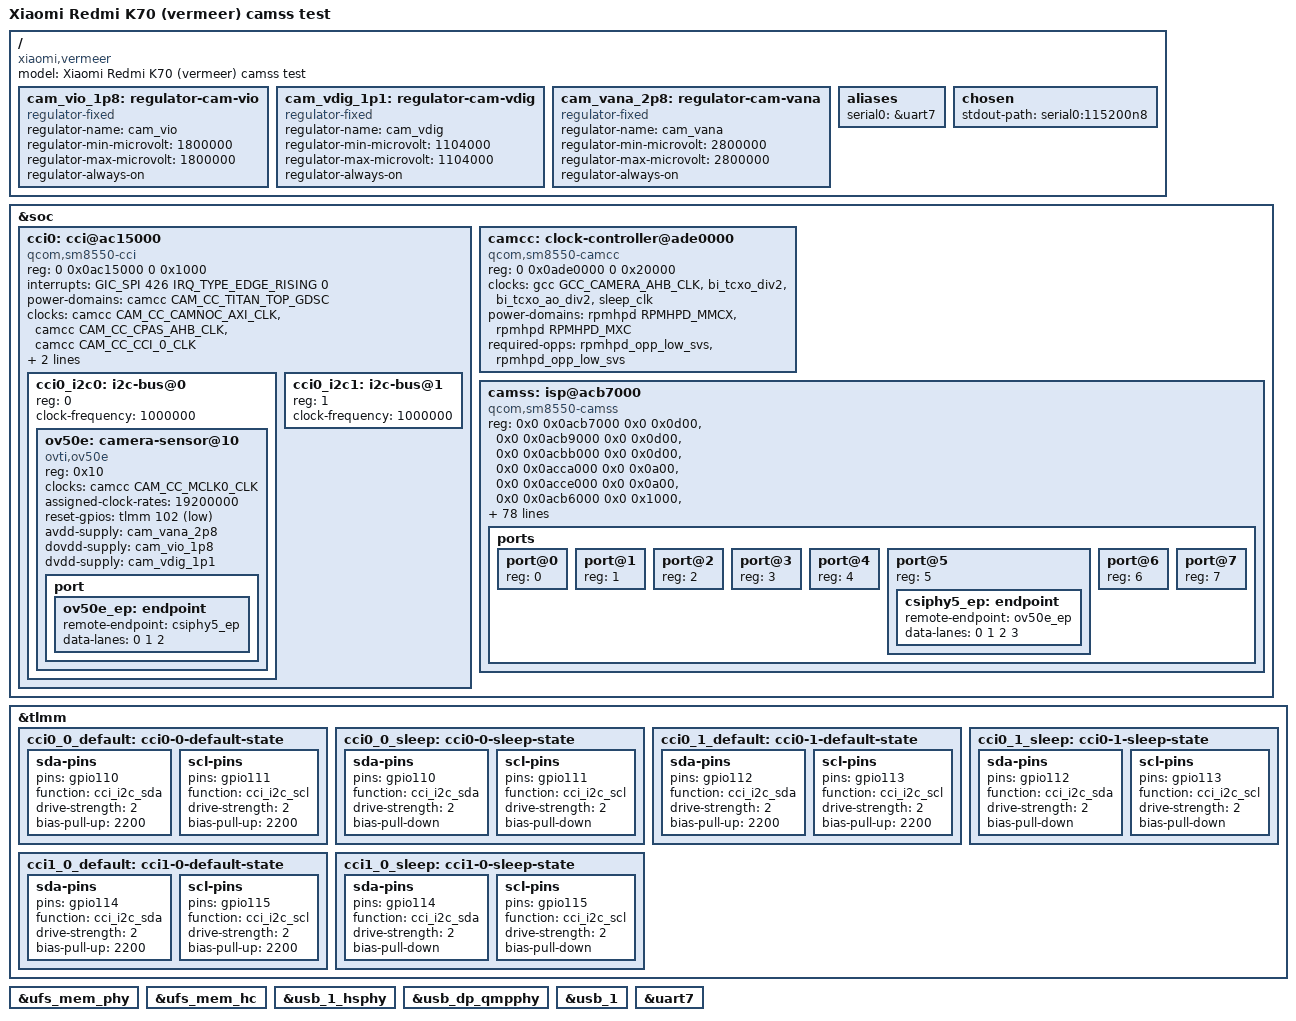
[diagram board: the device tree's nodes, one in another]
// SPDX-License-Identifier: BSD-3-Clause
/*
 * vermeer (Redmi K70, SM8550/kalama) camera bring-up test DT.
 * Xiaomi stripped all camera nodes from the stock DTBs (verified across
 * vendor_boot 8-FDT blob, dtbo.img 32 entries, boot.img) so this file
 * re-creates them from upstream sm8550.dtsi (camss/cci/camcc blocks are
 * platform constants) plus the vermeer sensor facts extracted from the
 * stock super.img odm partition:
 *   main: OV50E (OVX8000) @ CCI0/I2C0, 7-bit 0x10, chip id 0x5045
 *   rails: cam_vio=1.8V cam_vdig=1.1V cam_vana=2.8V (fixed placeholders
 *          until the real PM8550 LDO mapping is confirmed on-device)
 */
/dts-v1/;

#include "sm8550.dtsi"
#include <dt-bindings/clock/qcom,sm8550-camcc.h>
/* interconnect ids + tags (dtsi pulls sm8550-rpmh.h but not qcom,icc.h;
   be explicit so the camss interconnects below always resolve) */
#include <dt-bindings/interconnect/qcom,sm8550-rpmh.h>
#include <dt-bindings/interconnect/qcom,icc.h>

/ {
	model = "Xiaomi Redmi K70 (vermeer) camss test";
	compatible = "xiaomi,vermeer", "qcom,sm8550";

	cam_vio_1p8: regulator-cam-vio {
		compatible = "regulator-fixed";
		regulator-name = "cam_vio";
		regulator-min-microvolt = <1800000>;
		regulator-max-microvolt = <1800000>;
		regulator-always-on;
	};

	cam_vdig_1p1: regulator-cam-vdig {
		compatible = "regulator-fixed";
		regulator-name = "cam_vdig";
		regulator-min-microvolt = <1104000>;
		regulator-max-microvolt = <1104000>;
		regulator-always-on;
	};

	cam_vana_2p8: regulator-cam-vana {
		compatible = "regulator-fixed";
		regulator-name = "cam_vana";
		regulator-min-microvolt = <2800000>;
		regulator-max-microvolt = <2800000>;
		regulator-always-on;
	};
};

&soc {
		cci0: cci@ac15000 {
			compatible = "qcom,sm8550-cci", "qcom,msm8996-cci";
			reg = <0 0x0ac15000 0 0x1000>;
			interrupts = <GIC_SPI 426 IRQ_TYPE_EDGE_RISING 0>;
			power-domains = <&camcc CAM_CC_TITAN_TOP_GDSC>;
			clocks = <&camcc CAM_CC_CAMNOC_AXI_CLK>,
				 <&camcc CAM_CC_CPAS_AHB_CLK>,
				 <&camcc CAM_CC_CCI_0_CLK>;
			clock-names = "camnoc_axi",
				      "cpas_ahb",
				      "cci";
			pinctrl-0 = <&cci0_0_default &cci0_1_default>;
			pinctrl-1 = <&cci0_0_sleep &cci0_1_sleep>;
			pinctrl-names = "default", "sleep";
			status = "okay";
			#address-cells = <1>;
			#size-cells = <0>;

			cci0_i2c0: i2c-bus@0 {
				reg = <0>;
				clock-frequency = <1000000>;
				#address-cells = <1>;
				#size-cells = <0>;
			
		ov50e: camera-sensor@10 {
			compatible = "ovti,ov50e";
			reg = <0x10>;

			clocks = <&camcc CAM_CC_MCLK0_CLK>;
			clock-names = "xclk";
			/* vermeer dtbo: clock-rates = <19200000>; reset via gpio102,
			   gpio118 = custom (lens/ois power) - see overlay gpios tbl */
			assigned-clock-rates = <19200000>;
			reset-gpios = <&tlmm 102 GPIO_ACTIVE_LOW>;

			avdd-supply = <&cam_vana_2p8>;
			dovdd-supply = <&cam_vio_1p8>;
			dvdd-supply = <&cam_vdig_1p1>;

			status = "okay";

			port {
				ov50e_ep: endpoint {
					remote-endpoint = <&csiphy5_ep>;
					data-lanes = <0 1 2>;
				};
			};
		};
			};

			cci0_i2c1: i2c-bus@1 {
				reg = <1>;
				clock-frequency = <1000000>;
				#address-cells = <1>;
				#size-cells = <0>;
			};
		};

		camcc: clock-controller@ade0000 {
			compatible = "qcom,sm8550-camcc";
			reg = <0 0x0ade0000 0 0x20000>;
			clocks = <&gcc GCC_CAMERA_AHB_CLK>,
				 <&bi_tcxo_div2>,
				 <&bi_tcxo_ao_div2>,
				 <&sleep_clk>;
			power-domains = <&rpmhpd RPMHPD_MMCX>,
					<&rpmhpd RPMHPD_MXC>;
			required-opps = <&rpmhpd_opp_low_svs>,
					<&rpmhpd_opp_low_svs>;
			#clock-cells = <1>;
			#reset-cells = <1>;
			#power-domain-cells = <1>;
		};

		camss: isp@acb7000 {
			compatible = "qcom,sm8550-camss";

			reg = <0x0 0x0acb7000 0x0 0x0d00>,
			      <0x0 0x0acb9000 0x0 0x0d00>,
			      <0x0 0x0acbb000 0x0 0x0d00>,
			      <0x0 0x0acca000 0x0 0x0a00>,
			      <0x0 0x0acce000 0x0 0x0a00>,
			      <0x0 0x0acb6000 0x0 0x1000>,
			      <0x0 0x0ace4000 0x0 0x2000>,
			      <0x0 0x0ace6000 0x0 0x2000>,
			      <0x0 0x0ace8000 0x0 0x2000>,
			      <0x0 0x0acea000 0x0 0x2000>,
			      <0x0 0x0acec000 0x0 0x2000>,
			      <0x0 0x0acee000 0x0 0x2000>,
			      <0x0 0x0acf0000 0x0 0x2000>,
			      <0x0 0x0acf2000 0x0 0x2000>,
			      <0x0 0x0ac62000 0x0 0xf000>,
			      <0x0 0x0ac71000 0x0 0xf000>,
			      <0x0 0x0ac80000 0x0 0xf000>,
			      <0x0 0x0accb000 0x0 0x1800>,
			      <0x0 0x0accf000 0x0 0x1800>;
			reg-names = "csid0",
				    "csid1",
				    "csid2",
				    "csid_lite0",
				    "csid_lite1",
				    "csid_wrapper",
				    "csiphy0",
				    "csiphy1",
				    "csiphy2",
				    "csiphy3",
				    "csiphy4",
				    "csiphy5",
				    "csiphy6",
				    "csiphy7",
				    "vfe0",
				    "vfe1",
				    "vfe2",
				    "vfe_lite0",
				    "vfe_lite1";

			clocks = <&camcc CAM_CC_CAMNOC_AXI_CLK>,
				 <&camcc CAM_CC_CPAS_AHB_CLK>,
				 <&camcc CAM_CC_CPAS_FAST_AHB_CLK>,
				 <&camcc CAM_CC_CPAS_IFE_LITE_CLK>,
				 <&camcc CAM_CC_CPAS_IFE_0_CLK>,
				 <&camcc CAM_CC_CPAS_IFE_1_CLK>,
				 <&camcc CAM_CC_CPAS_IFE_2_CLK>,
				 <&camcc CAM_CC_CSID_CLK>,
				 <&camcc CAM_CC_CSIPHY0_CLK>,
				 <&camcc CAM_CC_CSI0PHYTIMER_CLK>,
				 <&camcc CAM_CC_CSIPHY1_CLK>,
				 <&camcc CAM_CC_CSI1PHYTIMER_CLK>,
				 <&camcc CAM_CC_CSIPHY2_CLK>,
				 <&camcc CAM_CC_CSI2PHYTIMER_CLK>,
				 <&camcc CAM_CC_CSIPHY3_CLK>,
				 <&camcc CAM_CC_CSI3PHYTIMER_CLK>,
				 <&camcc CAM_CC_CSIPHY4_CLK>,
				 <&camcc CAM_CC_CSI4PHYTIMER_CLK>,
				 <&camcc CAM_CC_CSIPHY5_CLK>,
				 <&camcc CAM_CC_CSI5PHYTIMER_CLK>,
				 <&camcc CAM_CC_CSIPHY6_CLK>,
				 <&camcc CAM_CC_CSI6PHYTIMER_CLK>,
				 <&camcc CAM_CC_CSIPHY7_CLK>,
				 <&camcc CAM_CC_CSI7PHYTIMER_CLK>,
				 <&camcc CAM_CC_CSID_CSIPHY_RX_CLK>,
				 <&gcc GCC_CAMERA_HF_AXI_CLK>,
				 <&camcc CAM_CC_IFE_0_CLK>,
				 <&camcc CAM_CC_IFE_0_FAST_AHB_CLK>,
				 <&camcc CAM_CC_IFE_1_CLK>,
				 <&camcc CAM_CC_IFE_1_FAST_AHB_CLK>,
				 <&camcc CAM_CC_IFE_2_CLK>,
				 <&camcc CAM_CC_IFE_2_FAST_AHB_CLK>,
				 <&camcc CAM_CC_IFE_LITE_CLK>,
				 <&camcc CAM_CC_IFE_LITE_AHB_CLK>,
				 <&camcc CAM_CC_IFE_LITE_CPHY_RX_CLK>,
				 <&camcc CAM_CC_IFE_LITE_CSID_CLK>;
			clock-names = "camnoc_axi",
				      "cpas_ahb",
				      "cpas_fast_ahb_clk",
				      "cpas_ife_lite",
				      "cpas_vfe0",
				      "cpas_vfe1",
				      "cpas_vfe2",
				      "csid",
				      "csiphy0",
				      "csiphy0_timer",
				      "csiphy1",
				      "csiphy1_timer",
				      "csiphy2",
				      "csiphy2_timer",
				      "csiphy3",
				      "csiphy3_timer",
				      "csiphy4",
				      "csiphy4_timer",
				      "csiphy5",
				      "csiphy5_timer",
				      "csiphy6",
				      "csiphy6_timer",
				      "csiphy7",
				      "csiphy7_timer",
				      "csiphy_rx",
				      "gcc_axi_hf",
				      "vfe0",
				      "vfe0_fast_ahb",
				      "vfe1",
				      "vfe1_fast_ahb",
				      "vfe2",
				      "vfe2_fast_ahb",
				      "vfe_lite",
				      "vfe_lite_ahb",
				      "vfe_lite_cphy_rx",
				      "vfe_lite_csid";

			interrupts = <GIC_SPI 601 IRQ_TYPE_EDGE_RISING 0>,
				     <GIC_SPI 603 IRQ_TYPE_EDGE_RISING 0>,
				     <GIC_SPI 431 IRQ_TYPE_EDGE_RISING 0>,
				     <GIC_SPI 605 IRQ_TYPE_EDGE_RISING 0>,
				     <GIC_SPI 376 IRQ_TYPE_EDGE_RISING 0>,
				     <GIC_SPI 477 IRQ_TYPE_EDGE_RISING 0>,
				     <GIC_SPI 478 IRQ_TYPE_EDGE_RISING 0>,
				     <GIC_SPI 479 IRQ_TYPE_EDGE_RISING 0>,
				     <GIC_SPI 448 IRQ_TYPE_EDGE_RISING 0>,
				     <GIC_SPI 122 IRQ_TYPE_EDGE_RISING 0>,
				     <GIC_SPI 89 IRQ_TYPE_EDGE_RISING 0>,
				     <GIC_SPI 278 IRQ_TYPE_EDGE_RISING 0>,
				     <GIC_SPI 277 IRQ_TYPE_EDGE_RISING 0>,
				     <GIC_SPI 602 IRQ_TYPE_EDGE_RISING 0>,
				     <GIC_SPI 604 IRQ_TYPE_EDGE_RISING 0>,
				     <GIC_SPI 688 IRQ_TYPE_EDGE_RISING 0>,
				     <GIC_SPI 606 IRQ_TYPE_EDGE_RISING 0>,
				     <GIC_SPI 377 IRQ_TYPE_EDGE_RISING 0>;
			interrupt-names = "csid0",
					  "csid1",
					  "csid2",
					  "csid_lite0",
					  "csid_lite1",
					  "csiphy0",
					  "csiphy1",
					  "csiphy2",
					  "csiphy3",
					  "csiphy4",
					  "csiphy5",
					  "csiphy6",
					  "csiphy7",
					  "vfe0",
					  "vfe1",
					  "vfe2",
					  "vfe_lite0",
					  "vfe_lite1";

			interconnects = <&gem_noc MASTER_APPSS_PROC QCOM_ICC_TAG_ACTIVE_ONLY
					 &config_noc SLAVE_CAMERA_CFG QCOM_ICC_TAG_ACTIVE_ONLY>,
					<&mmss_noc MASTER_CAMNOC_HF QCOM_ICC_TAG_ALWAYS
					 &mc_virt SLAVE_EBI1 QCOM_ICC_TAG_ALWAYS>;
			interconnect-names = "ahb",
					     "hf_0_mnoc";

			iommus = <&apps_smmu 0x800 0x20>;

			power-domains = <&camcc CAM_CC_IFE_0_GDSC>,
					<&camcc CAM_CC_IFE_1_GDSC>,
					<&camcc CAM_CC_IFE_2_GDSC>,
					<&camcc CAM_CC_TITAN_TOP_GDSC>;
			power-domain-names = "ife0",
					     "ife1",
					     "ife2",
					     "top";

			status = "okay";

			ports {
				#address-cells = <1>;
				#size-cells = <0>;

				port@0 {
					reg = <0>;
				};

				port@1 {
					reg = <1>;
				};

				port@2 {
					reg = <2>;
				};

				port@3 {
					reg = <3>;
				};

				port@4 {
					reg = <4>;
				};

				port@5 {
					reg = <5>;

					csiphy5_ep: endpoint {
						remote-endpoint = <&ov50e_ep>;
						/* OV50E main: 4-lane CSI-2 (D-PHY on csiphy5) */
						data-lanes = <0 1 2 3>;
					};
				};

				port@6 {
					reg = <6>;
				};

				port@7 {
					reg = <7>;
				};
			};
		};
};

&tlmm {
			cci0_0_default: cci0-0-default-state {
				sda-pins {
					pins = "gpio110";
					function = "cci_i2c_sda";
					drive-strength = <2>;
					bias-pull-up = <2200>;
				};

				scl-pins {
					pins = "gpio111";
					function = "cci_i2c_scl";
					drive-strength = <2>;
					bias-pull-up = <2200>;
				};
			};

			cci0_0_sleep: cci0-0-sleep-state {
				sda-pins {
					pins = "gpio110";
					function = "cci_i2c_sda";
					drive-strength = <2>;
					bias-pull-down;
				};

				scl-pins {
					pins = "gpio111";
					function = "cci_i2c_scl";
					drive-strength = <2>;
					bias-pull-down;
				};
			};

			cci0_1_default: cci0-1-default-state {
				sda-pins {
					pins = "gpio112";
					function = "cci_i2c_sda";
					drive-strength = <2>;
					bias-pull-up = <2200>;
				};

				scl-pins {
					pins = "gpio113";
					function = "cci_i2c_scl";
					drive-strength = <2>;
					bias-pull-up = <2200>;
				};
			};

			cci0_1_sleep: cci0-1-sleep-state {
				sda-pins {
					pins = "gpio112";
					function = "cci_i2c_sda";
					drive-strength = <2>;
					bias-pull-down;
				};

				scl-pins {
					pins = "gpio113";
					function = "cci_i2c_scl";
					drive-strength = <2>;
					bias-pull-down;
				};
			};

			cci1_0_default: cci1-0-default-state {
				sda-pins {
					pins = "gpio114";
					function = "cci_i2c_sda";
					drive-strength = <2>;
					bias-pull-up = <2200>;
				};

				scl-pins {
					pins = "gpio115";
					function = "cci_i2c_scl";
					drive-strength = <2>;
					bias-pull-up = <2200>;
				};
			};

			cci1_0_sleep: cci1-0-sleep-state {
				sda-pins {
					pins = "gpio114";
					function = "cci_i2c_sda";
					drive-strength = <2>;
					bias-pull-down;
				};

				scl-pins {
					pins = "gpio115";
					function = "cci_i2c_scl";
					drive-strength = <2>;
					bias-pull-down;
				};
			};
};

/* Boot-critical enables. The upstream sm8550.dtsi ships these nodes
 * disabled (a board dts normally enables them); vermeer needs them all
 * for first boot: UFS storage, USB (adb - the only debug channel with
 * msm_drm display absent), and the geni console UART.
 */

&ufs_mem_phy {
	status = "okay";
};

&ufs_mem_hc {
	status = "okay";
};

&usb_1_hsphy {
	status = "okay";
};

&usb_dp_qmpphy {
	status = "okay";
};

&usb_1 {
	status = "okay";
};

&uart7 {
	status = "okay";
};

/ {
	aliases {
		serial0 = &uart7;
	};

	chosen {
		stdout-path = "serial0:115200n8";
	};
};
